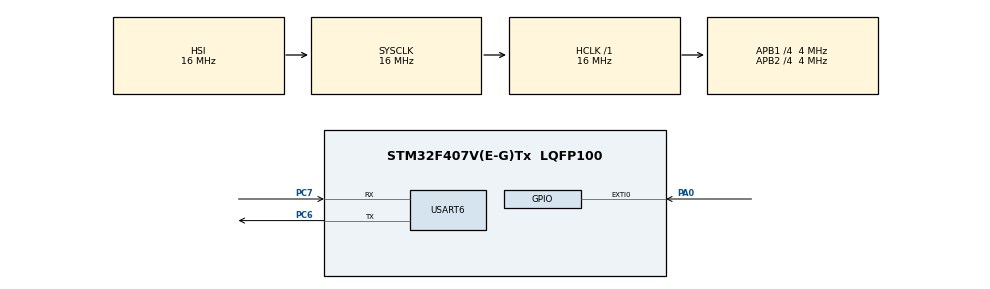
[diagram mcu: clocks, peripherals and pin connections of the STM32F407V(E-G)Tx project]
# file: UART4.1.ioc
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Mcu.Family=STM32F4
Mcu.Name=STM32F407V(E-G)Tx
Mcu.Package=LQFP100
NVIC.EXTI0_IRQn=true\:0\:0\:false\:false\:true\:true\:true\:true
NVIC.PriorityGroup=NVIC_PRIORITYGROUP_0
NVIC.USART6_IRQn=true\:0\:0\:false\:false\:true\:true\:true\:true
PA0-WKUP.Signal=GPXTI0
PA13.Mode=Serial_Wire
PA13.Signal=SYS_JTMS-SWDIO
PA14.Mode=Serial_Wire
PA14.Signal=SYS_JTCK-SWCLK
PC6.Mode=Asynchronous
PC6.Signal=USART6_TX
PC7.Mode=Asynchronous
PC7.Signal=USART6_RX
ProjectManager.HeapSize=0x200
ProjectManager.StackSize=0x400
ProjectManager.TargetToolchain=MDK-ARM V5.32
RCC.48MHZClocksFreq_Value=14285714.285714285
RCC.AHBFreq_Value=16000000
RCC.APB1CLKDivider=RCC_HCLK_DIV4
RCC.APB1Freq_Value=4000000
RCC.APB1TimFreq_Value=8000000
RCC.APB2CLKDivider=RCC_HCLK_DIV4
RCC.APB2Freq_Value=4000000
RCC.APB2TimFreq_Value=8000000
RCC.CortexFreq_Value=16000000
RCC.HCLKFreq_Value=16000000
RCC.HSE_VALUE=8000000
RCC.HSI_VALUE=16000000
RCC.LSE_VALUE=32768
RCC.PLLM=8
RCC.PLLN=50
RCC.PLLQ=7
RCC.SYSCLKFreq_VALUE=16000000
RCC.VCOOutputFreq_Value=100000000
USART6.VirtualMode=VM_ASYNC
board=STM32F407G-DISC1

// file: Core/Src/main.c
/* USER CODE BEGIN Header */
/**
  ******************************************************************************
  * @file           : main.c
  * @brief          : Main program body
  ******************************************************************************
  * @attention
  *
  * Copyright (c) 2022 STMicroelectronics.
  * All rights reserved.
  *
  * This software is licensed under terms that can be found in the LICENSE file
  * in the root directory of this software component.
  * If no LICENSE file comes with this software, it is provided AS-IS.
  *
  ******************************************************************************
  */
/* USER CODE END Header */
#include "main.h"

 UART_HandleTypeDef huart6;

/* USER CODE BEGIN PV */
char string[3]={"\n\r"};
 char string1[100]= {"\n\rprogram running\n\r"};
int flag=0;
/* USER CODE END PV */

void SystemClock_Config(void);
static void MX_GPIO_Init(void);
static void MX_USART6_UART_Init(void);
/* USER CODE BEGIN PFP */
void HAL_UART_RxCpltCallback(UART_HandleTypeDef *huart)
{

while(1)
{
	HAL_UART_Transmit(&huart6, (uint8_t *) string, sizeof(string), 1000);

}
}

/* USER CODE END PFP */

int main(void)
{

  /* MCU Configuration--------------------------------------------------------*/

  /* Reset of all peripherals, Initializes the Flash interface and the Systick. */
  HAL_Init();

  /* Configure the system clock */
  SystemClock_Config();

  /* Initialize all configured peripherals */
  MX_GPIO_Init();
  MX_USART6_UART_Init();
  /* USER CODE BEGIN 2 */
   HAL_UART_Receive_IT(&huart6, (uint8_t *)string, sizeof(string));
  /* USER CODE END 2 */

  /* Infinite loop */
  /* USER CODE BEGIN WHILE */

		while(1)
		{
			HAL_UART_Transmit(&huart6, (uint8_t *)string1, sizeof(string1), 2000);
			HAL_Delay(1000);
		}

    /* USER CODE END WHILE */

}

void SystemClock_Config(void)
{
  RCC_OscInitTypeDef RCC_OscInitStruct = {0};
  RCC_ClkInitTypeDef RCC_ClkInitStruct = {0};

  /** Configure the main internal regulator output voltage
  */
  __HAL_RCC_PWR_CLK_ENABLE();
  __HAL_PWR_VOLTAGESCALING_CONFIG(PWR_REGULATOR_VOLTAGE_SCALE1);

  /** Initializes the RCC Oscillators according to the specified parameters
  * in the RCC_OscInitTypeDef structure.
  */
  RCC_OscInitStruct.OscillatorType = RCC_OSCILLATORTYPE_HSI;
  RCC_OscInitStruct.HSIState = RCC_HSI_ON;
  RCC_OscInitStruct.HSICalibrationValue = RCC_HSICALIBRATION_DEFAULT;
  RCC_OscInitStruct.PLL.PLLState = RCC_PLL_NONE;
  if (HAL_RCC_OscConfig(&RCC_OscInitStruct) != HAL_OK)
  {
    Error_Handler();
  }

  /** Initializes the CPU, AHB and APB buses clocks
  */
  RCC_ClkInitStruct.ClockType = RCC_CLOCKTYPE_HCLK|RCC_CLOCKTYPE_SYSCLK
                              |RCC_CLOCKTYPE_PCLK1|RCC_CLOCKTYPE_PCLK2;
  RCC_ClkInitStruct.SYSCLKSource = RCC_SYSCLKSOURCE_HSI;
  RCC_ClkInitStruct.AHBCLKDivider = RCC_SYSCLK_DIV1;
  RCC_ClkInitStruct.APB1CLKDivider = RCC_HCLK_DIV4;
  RCC_ClkInitStruct.APB2CLKDivider = RCC_HCLK_DIV4;

  if (HAL_RCC_ClockConfig(&RCC_ClkInitStruct, FLASH_LATENCY_0) != HAL_OK)
  {
    Error_Handler();
  }
}

static void MX_USART6_UART_Init(void)
{

  huart6.Instance = USART6;
  huart6.Init.BaudRate = 115200;
  huart6.Init.WordLength = UART_WORDLENGTH_8B;
  huart6.Init.StopBits = UART_STOPBITS_1;
  huart6.Init.Parity = UART_PARITY_NONE;
  huart6.Init.Mode = UART_MODE_TX_RX;
  huart6.Init.HwFlowCtl = UART_HWCONTROL_NONE;
  huart6.Init.OverSampling = UART_OVERSAMPLING_16;
  if (HAL_UART_Init(&huart6) != HAL_OK)
  {
    Error_Handler();
  }

}

static void MX_GPIO_Init(void)
{
  GPIO_InitTypeDef GPIO_InitStruct = {0};

  /* GPIO Ports Clock Enable */
  __HAL_RCC_GPIOA_CLK_ENABLE();
  __HAL_RCC_GPIOC_CLK_ENABLE();

  /*Configure GPIO pin : PA0 */
  GPIO_InitStruct.Pin = GPIO_PIN_0;
  GPIO_InitStruct.Mode = GPIO_MODE_IT_RISING;
  GPIO_InitStruct.Pull = GPIO_NOPULL;
  HAL_GPIO_Init(GPIOA, &GPIO_InitStruct);

  /* EXTI interrupt init*/
  HAL_NVIC_SetPriority(EXTI0_IRQn, 0, 0);
  HAL_NVIC_EnableIRQ(EXTI0_IRQn);

}

void Error_Handler(void)
{
  __disable_irq();
  while (1)
  {
  }
}
